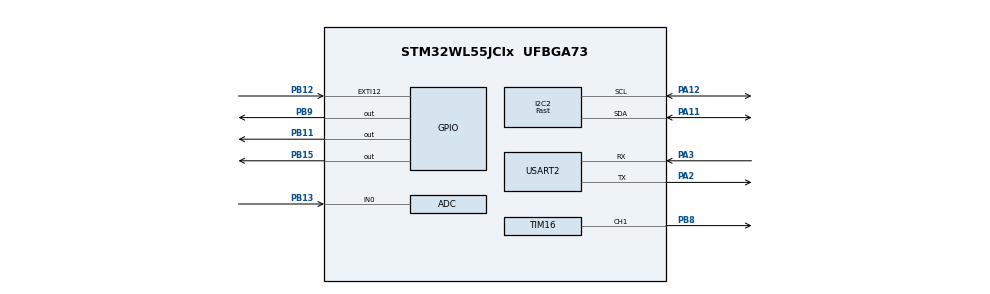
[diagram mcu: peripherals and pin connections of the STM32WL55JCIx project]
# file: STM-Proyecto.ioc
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ADC.ClockPrescaler=ADC_CLOCK_SYNC_PCLK_DIV4
ADC.ContinuousConvMode=DISABLE
ADC.EOCSelection=ADC_EOC_SINGLE_CONV
ADC.NbrOfConversion=1
ADC.OversamplingMode=DISABLE
ADC.Resolution=ADC_RESOLUTION_12B
ADC.SamplingTimeCommon1=ADC_SAMPLETIME_160CYCLES_5
ADC.SamplingTimeCommon2=ADC_SAMPLETIME_160CYCLES_5
ADC.SelectedChannel=ADC_CHANNEL_0
FREERTOS.Events01=event_flags,Static,event_flagsControlBlock
FREERTOS.Queues01=serial_tx_data_queue,64,uint64_t,0,Static,serial_tx_data_queueBuffer,serial_tx_data_queueControlBlock
FREERTOS.Tasks01=uart_tx_task,24,128,uart_tx_task_routine,Default,NULL,Static,uart_tx_taskBuffer,uart_tx_taskControlBlock;uart_rx_task,24,128,uart_rx_task_routine,Default,NULL,Static,uart_rx_taskBuffer,uart_rx_taskControlBlock;sensor_i2c_task,24,128,sensor_i2c_task_routine,Default,NULL,Static,sensor_i2c_taskBuffer,sensor_i2c_taskControlBlock;light_adc_task,24,128,light_adc_task_routine,Default,NULL,Static,light_adc_taskBuffer,light_adc_taskControlBlock
I2C2.I2C_Speed_Mode=I2C_Fast
I2C2.Timing=0x00000003
Mcu.Family=STM32WL
Mcu.Name=STM32WL55JCIx
Mcu.Package=UFBGA73
NVIC.ADC_IRQn=true\:5\:0\:false\:false\:true\:true\:true\:true\:true
NVIC.EXTI15_10_IRQn=true\:5\:0\:false\:false\:true\:true\:true\:true\:true
NVIC.I2C2_ER_IRQn=true\:5\:0\:false\:false\:true\:true\:true\:true\:true
NVIC.I2C2_EV_IRQn=true\:5\:0\:false\:false\:true\:true\:true\:true\:true
NVIC.PriorityGroup=NVIC_PRIORITYGROUP_4
NVIC.USART2_IRQn=true\:5\:0\:false\:false\:true\:true\:true\:true\:true
PA11.Mode=I2C
PA11.Signal=I2C2_SDA
PA12.Mode=I2C
PA12.Signal=I2C2_SCL
PA2.Mode=Asynchronous
PA2.Signal=USART2_TX
PA3.Mode=Asynchronous
PA3.Signal=USART2_RX
PB11.Signal=GPIO_Output
PB12.Signal=GPXTI12
PB13.Mode=IN0
PB13.Signal=ADC_IN0
PB15.Signal=GPIO_Output
PB8.Signal=S_TIM16_CH1
PB9.Signal=GPIO_Output
ProjectManager.HeapSize=0x200
ProjectManager.StackSize=0x400
ProjectManager.TargetToolchain=STM32CubeIDE
RCC.HSE_VALUE=32000000
RCC.HSI_VALUE=16000000
RCC.LSE_VALUE=32768
RCC.VCOOutputFreq_Value=32000000
SH.S_TIM16_CH1.0=TIM16_CH1,PWM Generation1 CH1
TIM16.AutoReloadPreload=TIM_AUTORELOAD_PRELOAD_ENABLE
TIM16.Channel=TIM_CHANNEL_1
TIM16.ClockDivision=TIM_CLOCKDIVISION_DIV2
TIM16.OCFastMode_PWM=TIM_OCFAST_ENABLE
TIM16.Period=40000-1
TIM16.Prescaler=2
TIM16.Pulse=2000
USART2.FIFOMode=FIFOMODE_ENABLE
USART2.RXFIFOThreshold=RXFIFO_THRESHOLD_7EIGHTHFULL
USART2.VirtualMode-Asynchronous=VM_ASYNC
VP_FREERTOS_VS_CMSIS_V2.Mode=CMSIS_V2
VP_TIM16_VS_ClockSourceINT.Mode=Enable_Timer
board=NUCLEO-WL55JC1

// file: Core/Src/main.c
/* USER CODE BEGIN Header */
/**
  ******************************************************************************
  * @file           : main.c
  * @brief          : Main program body
  ******************************************************************************
  * @attention
  *
  * Copyright (c) 2024 STMicroelectronics.
  * All rights reserved.
  *
  * This software is licensed under terms that can be found in the LICENSE file
  * in the root directory of this software component.
  * If no LICENSE file comes with this software, it is provided AS-IS.
  *
  ******************************************************************************
  */
/* USER CODE END Header */
#include "main.h"
#include "cmsis_os.h"

typedef StaticTask_t osStaticThreadDef_t;
typedef StaticQueue_t osStaticMessageQDef_t;
typedef StaticEventGroup_t osStaticEventGroupDef_t;

ADC_HandleTypeDef hadc;

I2C_HandleTypeDef hi2c2;

TIM_HandleTypeDef htim16;

UART_HandleTypeDef huart2;

/* Definitions for uart_tx_task */
osThreadId_t uart_tx_taskHandle;
uint32_t uart_tx_taskBuffer[ 128 ];
osStaticThreadDef_t uart_tx_taskControlBlock;
const osThreadAttr_t uart_tx_task_attributes = {
  .name = "uart_tx_task",
  .stack_mem = &uart_tx_taskBuffer[0],
  .stack_size = sizeof(uart_tx_taskBuffer),
  .cb_mem = &uart_tx_taskControlBlock,
  .cb_size = sizeof(uart_tx_taskControlBlock),
  .priority = (osPriority_t) osPriorityNormal,
};
/* Definitions for uart_rx_task */
osThreadId_t uart_rx_taskHandle;
uint32_t uart_rx_taskBuffer[ 128 ];
osStaticThreadDef_t uart_rx_taskControlBlock;
const osThreadAttr_t uart_rx_task_attributes = {
  .name = "uart_rx_task",
  .stack_mem = &uart_rx_taskBuffer[0],
  .stack_size = sizeof(uart_rx_taskBuffer),
  .cb_mem = &uart_rx_taskControlBlock,
  .cb_size = sizeof(uart_rx_taskControlBlock),
  .priority = (osPriority_t) osPriorityNormal,
};
/* Definitions for sensor_i2c_task */
osThreadId_t sensor_i2c_taskHandle;
uint32_t sensor_i2c_taskBuffer[ 128 ];
osStaticThreadDef_t sensor_i2c_taskControlBlock;
const osThreadAttr_t sensor_i2c_task_attributes = {
  .name = "sensor_i2c_task",
  .stack_mem = &sensor_i2c_taskBuffer[0],
  .stack_size = sizeof(sensor_i2c_taskBuffer),
  .cb_mem = &sensor_i2c_taskControlBlock,
  .cb_size = sizeof(sensor_i2c_taskControlBlock),
  .priority = (osPriority_t) osPriorityNormal,
};
/* Definitions for light_adc_task */
osThreadId_t light_adc_taskHandle;
uint32_t light_adc_taskBuffer[ 128 ];
osStaticThreadDef_t light_adc_taskControlBlock;
const osThreadAttr_t light_adc_task_attributes = {
  .name = "light_adc_task",
  .stack_mem = &light_adc_taskBuffer[0],
  .stack_size = sizeof(light_adc_taskBuffer),
  .cb_mem = &light_adc_taskControlBlock,
  .cb_size = sizeof(light_adc_taskControlBlock),
  .priority = (osPriority_t) osPriorityNormal,
};
/* Definitions for serial_tx_data_queue */
osMessageQueueId_t serial_tx_data_queueHandle;
uint8_t serial_tx_data_queueBuffer[ 64 * sizeof( uint64_t ) ];
osStaticMessageQDef_t serial_tx_data_queueControlBlock;
const osMessageQueueAttr_t serial_tx_data_queue_attributes = {
  .name = "serial_tx_data_queue",
  .cb_mem = &serial_tx_data_queueControlBlock,
  .cb_size = sizeof(serial_tx_data_queueControlBlock),
  .mq_mem = &serial_tx_data_queueBuffer,
  .mq_size = sizeof(serial_tx_data_queueBuffer)
};
/* Definitions for event_flags */
osEventFlagsId_t event_flagsHandle;
osStaticEventGroupDef_t event_flagsControlBlock;
const osEventFlagsAttr_t event_flags_attributes = {
  .name = "event_flags",
  .cb_mem = &event_flagsControlBlock,
  .cb_size = sizeof(event_flagsControlBlock),
};

void SystemClock_Config(void);
static void MX_GPIO_Init(void);
static void MX_ADC_Init(void);
static void MX_I2C2_Init(void);
static void MX_USART2_UART_Init(void);
static void MX_TIM16_Init(void);
void uart_tx_task_routine(void *argument);
void uart_rx_task_routine(void *argument);
void sensor_i2c_task_routine(void *argument);
void light_adc_task_routine(void *argument);

int main(void)
{

  /* MCU Configuration--------------------------------------------------------*/

  /* Reset of all peripherals, Initializes the Flash interface and the Systick. */
  HAL_Init();

  /* Configure the system clock */
  SystemClock_Config();

  /* Initialize all configured peripherals */
  MX_GPIO_Init();
  MX_ADC_Init();
  MX_I2C2_Init();
  MX_USART2_UART_Init();
  MX_TIM16_Init();

  /* Init scheduler */
  osKernelInitialize();

  /* Create the queue(s) */
  /* creation of serial_tx_data_queue */
  serial_tx_data_queueHandle = osMessageQueueNew (64, sizeof(uint64_t), &serial_tx_data_queue_attributes);

  /* Create the thread(s) */
  /* creation of uart_tx_task */
  uart_tx_taskHandle = osThreadNew(uart_tx_task_routine, NULL, &uart_tx_task_attributes);

  /* creation of uart_rx_task */
  uart_rx_taskHandle = osThreadNew(uart_rx_task_routine, NULL, &uart_rx_task_attributes);

  /* creation of sensor_i2c_task */
  sensor_i2c_taskHandle = osThreadNew(sensor_i2c_task_routine, NULL, &sensor_i2c_task_attributes);

  /* creation of light_adc_task */
  light_adc_taskHandle = osThreadNew(light_adc_task_routine, NULL, &light_adc_task_attributes);

  /* Create the event(s) */
  /* creation of event_flags */
  event_flagsHandle = osEventFlagsNew(&event_flags_attributes);

  /* Start scheduler */
  osKernelStart();

  /* We should never get here as control is now taken by the scheduler */

  /* Infinite loop */
  while (1)
  {

  }
}

void SystemClock_Config(void)
{
  RCC_OscInitTypeDef RCC_OscInitStruct = {0};
  RCC_ClkInitTypeDef RCC_ClkInitStruct = {0};

  /** Configure the main internal regulator output voltage
  */
  __HAL_PWR_VOLTAGESCALING_CONFIG(PWR_REGULATOR_VOLTAGE_SCALE2);

  /** Initializes the CPU, AHB and APB buses clocks
  */
  RCC_OscInitStruct.OscillatorType = RCC_OSCILLATORTYPE_MSI;
  RCC_OscInitStruct.MSIState = RCC_MSI_ON;
  RCC_OscInitStruct.MSICalibrationValue = RCC_MSICALIBRATION_DEFAULT;
  RCC_OscInitStruct.MSIClockRange = RCC_MSIRANGE_6;
  RCC_OscInitStruct.PLL.PLLState = RCC_PLL_NONE;
  if (HAL_RCC_OscConfig(&RCC_OscInitStruct) != HAL_OK)
  {
    Error_Handler();
  }

  /** Configure the SYSCLKSource, HCLK, PCLK1 and PCLK2 clocks dividers
  */
  RCC_ClkInitStruct.ClockType = RCC_CLOCKTYPE_HCLK3|RCC_CLOCKTYPE_HCLK
                              |RCC_CLOCKTYPE_SYSCLK|RCC_CLOCKTYPE_PCLK1
                              |RCC_CLOCKTYPE_PCLK2;
  RCC_ClkInitStruct.SYSCLKSource = RCC_SYSCLKSOURCE_MSI;
  RCC_ClkInitStruct.AHBCLKDivider = RCC_SYSCLK_DIV1;
  RCC_ClkInitStruct.APB1CLKDivider = RCC_HCLK_DIV1;
  RCC_ClkInitStruct.APB2CLKDivider = RCC_HCLK_DIV1;
  RCC_ClkInitStruct.AHBCLK3Divider = RCC_SYSCLK_DIV1;

  if (HAL_RCC_ClockConfig(&RCC_ClkInitStruct, FLASH_LATENCY_0) != HAL_OK)
  {
    Error_Handler();
  }
}

static void MX_ADC_Init(void)
{

  /** Configure the global features of the ADC (Clock, Resolution, Data Alignment and number of conversion)
  */
  hadc.Instance = ADC;
  hadc.Init.ClockPrescaler = ADC_CLOCK_SYNC_PCLK_DIV4;
  hadc.Init.Resolution = ADC_RESOLUTION_12B;
  hadc.Init.DataAlign = ADC_DATAALIGN_RIGHT;
  hadc.Init.ScanConvMode = ADC_SCAN_DISABLE;
  hadc.Init.EOCSelection = ADC_EOC_SINGLE_CONV;
  hadc.Init.LowPowerAutoWait = DISABLE;
  hadc.Init.LowPowerAutoPowerOff = DISABLE;
  hadc.Init.ContinuousConvMode = DISABLE;
  hadc.Init.NbrOfConversion = 1;
  hadc.Init.DiscontinuousConvMode = DISABLE;
  hadc.Init.ExternalTrigConv = ADC_SOFTWARE_START;
  hadc.Init.ExternalTrigConvEdge = ADC_EXTERNALTRIGCONVEDGE_NONE;
  hadc.Init.DMAContinuousRequests = DISABLE;
  hadc.Init.Overrun = ADC_OVR_DATA_PRESERVED;
  hadc.Init.SamplingTimeCommon1 = ADC_SAMPLETIME_160CYCLES_5;
  hadc.Init.SamplingTimeCommon2 = ADC_SAMPLETIME_160CYCLES_5;
  hadc.Init.OversamplingMode = DISABLE;
  hadc.Init.TriggerFrequencyMode = ADC_TRIGGER_FREQ_HIGH;
  if (HAL_ADC_Init(&hadc) != HAL_OK)
  {
    Error_Handler();
  }

}

static void MX_I2C2_Init(void)
{

  hi2c2.Instance = I2C2;
  hi2c2.Init.Timing = 0x00000003;
  hi2c2.Init.OwnAddress1 = 0;
  hi2c2.Init.AddressingMode = I2C_ADDRESSINGMODE_7BIT;
  hi2c2.Init.DualAddressMode = I2C_DUALADDRESS_DISABLE;
  hi2c2.Init.OwnAddress2 = 0;
  hi2c2.Init.OwnAddress2Masks = I2C_OA2_NOMASK;
  hi2c2.Init.GeneralCallMode = I2C_GENERALCALL_DISABLE;
  hi2c2.Init.NoStretchMode = I2C_NOSTRETCH_DISABLE;
  if (HAL_I2C_Init(&hi2c2) != HAL_OK)
  {
    Error_Handler();
  }

  /** Configure Analogue filter
  */
  if (HAL_I2CEx_ConfigAnalogFilter(&hi2c2, I2C_ANALOGFILTER_ENABLE) != HAL_OK)
  {
    Error_Handler();
  }

  /** Configure Digital filter
  */
  if (HAL_I2CEx_ConfigDigitalFilter(&hi2c2, 0) != HAL_OK)
  {
    Error_Handler();
  }

}

static void MX_TIM16_Init(void)
{

  TIM_OC_InitTypeDef sConfigOC = {0};
  TIM_BreakDeadTimeConfigTypeDef sBreakDeadTimeConfig = {0};

  htim16.Instance = TIM16;
  htim16.Init.Prescaler = 2;
  htim16.Init.CounterMode = TIM_COUNTERMODE_UP;
  htim16.Init.Period = 40000-1;
  htim16.Init.ClockDivision = TIM_CLOCKDIVISION_DIV2;
  htim16.Init.RepetitionCounter = 0;
  htim16.Init.AutoReloadPreload = TIM_AUTORELOAD_PRELOAD_ENABLE;
  if (HAL_TIM_Base_Init(&htim16) != HAL_OK)
  {
    Error_Handler();
  }
  if (HAL_TIM_PWM_Init(&htim16) != HAL_OK)
  {
    Error_Handler();
  }
  sConfigOC.OCMode = TIM_OCMODE_PWM1;
  sConfigOC.Pulse = 2000;
  sConfigOC.OCPolarity = TIM_OCPOLARITY_HIGH;
  sConfigOC.OCNPolarity = TIM_OCNPOLARITY_HIGH;
  sConfigOC.OCFastMode = TIM_OCFAST_ENABLE;
  sConfigOC.OCIdleState = TIM_OCIDLESTATE_RESET;
  sConfigOC.OCNIdleState = TIM_OCNIDLESTATE_RESET;
  if (HAL_TIM_PWM_ConfigChannel(&htim16, &sConfigOC, TIM_CHANNEL_1) != HAL_OK)
  {
    Error_Handler();
  }
  sBreakDeadTimeConfig.OffStateRunMode = TIM_OSSR_DISABLE;
  sBreakDeadTimeConfig.OffStateIDLEMode = TIM_OSSI_DISABLE;
  sBreakDeadTimeConfig.LockLevel = TIM_LOCKLEVEL_OFF;
  sBreakDeadTimeConfig.DeadTime = 0;
  sBreakDeadTimeConfig.BreakState = TIM_BREAK_DISABLE;
  sBreakDeadTimeConfig.BreakPolarity = TIM_BREAKPOLARITY_HIGH;
  sBreakDeadTimeConfig.BreakFilter = 0;
  sBreakDeadTimeConfig.AutomaticOutput = TIM_AUTOMATICOUTPUT_DISABLE;
  if (HAL_TIMEx_ConfigBreakDeadTime(&htim16, &sBreakDeadTimeConfig) != HAL_OK)
  {
    Error_Handler();
  }
  HAL_TIM_MspPostInit(&htim16);

}

static void MX_USART2_UART_Init(void)
{

  huart2.Instance = USART2;
  huart2.Init.BaudRate = 115200;
  huart2.Init.WordLength = UART_WORDLENGTH_8B;
  huart2.Init.StopBits = UART_STOPBITS_1;
  huart2.Init.Parity = UART_PARITY_NONE;
  huart2.Init.Mode = UART_MODE_TX_RX;
  huart2.Init.HwFlowCtl = UART_HWCONTROL_NONE;
  huart2.Init.OverSampling = UART_OVERSAMPLING_16;
  huart2.Init.OneBitSampling = UART_ONE_BIT_SAMPLE_DISABLE;
  huart2.Init.ClockPrescaler = UART_PRESCALER_DIV1;
  huart2.AdvancedInit.AdvFeatureInit = UART_ADVFEATURE_NO_INIT;
  if (HAL_UART_Init(&huart2) != HAL_OK)
  {
    Error_Handler();
  }
  if (HAL_UARTEx_SetTxFifoThreshold(&huart2, UART_TXFIFO_THRESHOLD_1_8) != HAL_OK)
  {
    Error_Handler();
  }
  if (HAL_UARTEx_SetRxFifoThreshold(&huart2, UART_RXFIFO_THRESHOLD_7_8) != HAL_OK)
  {
    Error_Handler();
  }
  if (HAL_UARTEx_EnableFifoMode(&huart2) != HAL_OK)
  {
    Error_Handler();
  }

}

static void MX_GPIO_Init(void)
{
  GPIO_InitTypeDef GPIO_InitStruct = {0};

  /* GPIO Ports Clock Enable */
  __HAL_RCC_GPIOA_CLK_ENABLE();
  __HAL_RCC_GPIOB_CLK_ENABLE();

  /*Configure GPIO pin Output Level */
  HAL_GPIO_WritePin(GPIOB, GPIO_PIN_15|GPIO_PIN_9|GPIO_PIN_11, GPIO_PIN_RESET);

  /*Configure GPIO pins : PB15 PB9 PB11 */
  GPIO_InitStruct.Pin = GPIO_PIN_15|GPIO_PIN_9|GPIO_PIN_11;
  GPIO_InitStruct.Mode = GPIO_MODE_OUTPUT_PP;
  GPIO_InitStruct.Pull = GPIO_NOPULL;
  GPIO_InitStruct.Speed = GPIO_SPEED_FREQ_LOW;
  HAL_GPIO_Init(GPIOB, &GPIO_InitStruct);

  /*Configure GPIO pin : PB12 */
  GPIO_InitStruct.Pin = GPIO_PIN_12;
  GPIO_InitStruct.Mode = GPIO_MODE_IT_RISING;
  GPIO_InitStruct.Pull = GPIO_NOPULL;
  HAL_GPIO_Init(GPIOB, &GPIO_InitStruct);

  /* EXTI interrupt init*/
  HAL_NVIC_SetPriority(EXTI15_10_IRQn, 5, 0);
  HAL_NVIC_EnableIRQ(EXTI15_10_IRQn);

}

/* USER CODE BEGIN 4 */

void uart_rx_task_pre_loop(void);
void sensor_i2c_task_pre_loop(void);
void light_adc_task_pre_loop(void);

void uart_tx_task_iteration(void);
void uart_rx_task_iteration(void);
void sensor_i2c_task_iteration(void);
void light_adc_task_iteration(void);

/* USER CODE END 4 */

void uart_tx_task_routine(void *argument)
{
  /* USER CODE BEGIN 5 */
  /* Infinite loop */
  for(;;)
  {
    uart_tx_task_iteration();
    osDelay(1);
  }
  /* USER CODE END 5 */
}

void uart_rx_task_routine(void *argument)
{
  /* USER CODE BEGIN uart_rx_task_routine */
  uart_rx_task_pre_loop();
  /* Infinite loop */
  for(;;)
  {
	uart_rx_task_iteration();
    osDelay(1);
  }
  /* USER CODE END uart_rx_task_routine */
}

void sensor_i2c_task_routine(void *argument)
{
  /* USER CODE BEGIN sensor_i2c_task_routine */
  sensor_i2c_task_pre_loop();
  /* Infinite loop */
  for(;;)
  {
    sensor_i2c_task_iteration();
    osDelay(1);
  }
  /* USER CODE END sensor_i2c_task_routine */
}

void light_adc_task_routine(void *argument)
{
  /* USER CODE BEGIN light_adc_task_routine */
  /* Infinite loop */
  for(;;)
  {
	osDelay(100); // 10Hz
    light_adc_task_iteration();
  }
  /* USER CODE END light_adc_task_routine */
}

void Error_Handler(void)
{
  __disable_irq();
  while (1)
  {
  }
}
